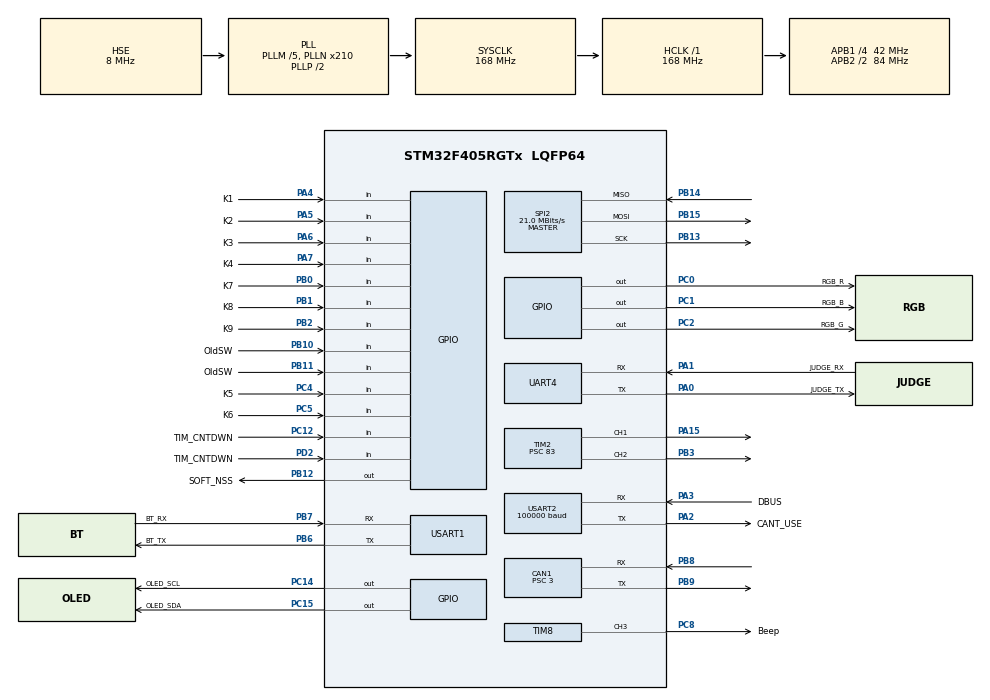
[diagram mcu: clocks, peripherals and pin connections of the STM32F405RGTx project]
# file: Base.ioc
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CAN1.ABOM=ENABLE
CAN1.BS1=CAN_BS1_9TQ
CAN1.BS2=CAN_BS2_4TQ
CAN1.CalculateTimeBit=1000
CAN1.CalculateTimeQuantum=71.42857142857143
CAN1.Prescaler=3
Dma.Request0=UART4_RX
Dma.Request1=USART1_RX
Dma.Request2=USART2_RX
Dma.UART4_RX.0.Channel=DMA_CHANNEL_4
Dma.UART4_RX.0.Direction=DMA_PERIPH_TO_MEMORY
Dma.UART4_RX.0.FIFOMode=DMA_FIFOMODE_DISABLE
Dma.UART4_RX.0.FIFOThreshold=DMA_FIFO_THRESHOLD_FULL
Dma.UART4_RX.0.Instance=DMA1_Stream2
Dma.UART4_RX.0.MemBurst=DMA_MBURST_SINGLE
Dma.UART4_RX.0.MemDataAlignment=DMA_MDATAALIGN_BYTE
Dma.UART4_RX.0.MemInc=DMA_MINC_ENABLE
Dma.UART4_RX.0.Mode=DMA_NORMAL
Dma.UART4_RX.0.PeriphBurst=DMA_PBURST_SINGLE
Dma.UART4_RX.0.PeriphDataAlignment=DMA_PDATAALIGN_BYTE
Dma.UART4_RX.0.PeriphInc=DMA_PINC_DISABLE
Dma.UART4_RX.0.Priority=DMA_PRIORITY_LOW
Dma.USART1_RX.1.Channel=DMA_CHANNEL_4
Dma.USART1_RX.1.Direction=DMA_PERIPH_TO_MEMORY
Dma.USART1_RX.1.FIFOMode=DMA_FIFOMODE_DISABLE
Dma.USART1_RX.1.FIFOThreshold=DMA_FIFO_THRESHOLD_FULL
Dma.USART1_RX.1.Instance=DMA2_Stream2
Dma.USART1_RX.1.MemBurst=DMA_MBURST_SINGLE
Dma.USART1_RX.1.MemDataAlignment=DMA_MDATAALIGN_BYTE
Dma.USART1_RX.1.MemInc=DMA_MINC_ENABLE
Dma.USART1_RX.1.Mode=DMA_NORMAL
Dma.USART1_RX.1.PeriphBurst=DMA_PBURST_SINGLE
Dma.USART1_RX.1.PeriphDataAlignment=DMA_PDATAALIGN_BYTE
Dma.USART1_RX.1.PeriphInc=DMA_PINC_DISABLE
Dma.USART1_RX.1.Priority=DMA_PRIORITY_LOW
Dma.USART2_RX.2.Channel=DMA_CHANNEL_4
Dma.USART2_RX.2.Direction=DMA_PERIPH_TO_MEMORY
Dma.USART2_RX.2.FIFOMode=DMA_FIFOMODE_DISABLE
Dma.USART2_RX.2.FIFOThreshold=DMA_FIFO_THRESHOLD_FULL
Dma.USART2_RX.2.Instance=DMA1_Stream5
Dma.USART2_RX.2.MemBurst=DMA_MBURST_SINGLE
Dma.USART2_RX.2.MemDataAlignment=DMA_MDATAALIGN_BYTE
Dma.USART2_RX.2.MemInc=DMA_MINC_ENABLE
Dma.USART2_RX.2.Mode=DMA_NORMAL
Dma.USART2_RX.2.PeriphBurst=DMA_PBURST_SINGLE
Dma.USART2_RX.2.PeriphDataAlignment=DMA_PDATAALIGN_BYTE
Dma.USART2_RX.2.PeriphInc=DMA_PINC_DISABLE
Dma.USART2_RX.2.Priority=DMA_PRIORITY_LOW
FREERTOS.INCLUDE_uxTaskGetStackHighWaterMark=0
FREERTOS.INCLUDE_vTaskDelayUntil=1
FREERTOS.Tasks01=defaultTask,-2,128,StartDefaultTask
FREERTOS.configUSE_TIMERS=1
Mcu.Family=STM32F4
Mcu.Name=STM32F405RGTx
Mcu.Package=LQFP64
NVIC.CAN1_RX0_IRQn=true\:6\:0\:true
NVIC.DMA1_Stream2_IRQn=true\:8\:0\:true
NVIC.DMA1_Stream5_IRQn=true\:8\:0\:true
NVIC.DMA2_Stream2_IRQn=true\:8\:0\:true
NVIC.PriorityGroup=NVIC_PRIORITYGROUP_4
NVIC.UART4_IRQn=true\:6\:0\:true
NVIC.USART1_IRQn=true\:7\:0\:true
NVIC.USART2_IRQn=true\:7\:0\:true
PA0-WKUP.GPIO_Label=JUDGE_TX
PA0-WKUP.GPIO_Mode=GPIO_MODE_AF_PP
PA0-WKUP.GPIO_PuPd=GPIO_PULLUP
PA0-WKUP.GPIO_Speed=GPIO_SPEED_HIGH
PA0-WKUP.Mode=Asynchronous
PA0-WKUP.Signal=UART4_TX
PA1.GPIO_Label=JUDGE_RX
PA1.GPIO_Mode=GPIO_MODE_AF_PP
PA1.GPIO_PuPd=GPIO_PULLUP
PA1.GPIO_Speed=GPIO_SPEED_HIGH
PA1.Mode=Asynchronous
PA1.Signal=UART4_RX
PA13.Mode=Serial-Wire
PA13.Signal=SYS_JTMS-SWDIO
PA14.Mode=Serial-Wire
PA14.Signal=SYS_JTCK-SWCLK
PA15.Signal=S_TIM2_CH1_ETR
PA2.GPIO_Label=CANT_USE
PA2.GPIO_Mode=GPIO_MODE_AF_PP
PA2.GPIO_PuPd=GPIO_PULLUP
PA2.GPIO_Speed=GPIO_SPEED_HIGH
PA2.Mode=Asynchronous
PA2.Signal=USART2_TX
PA3.GPIO_Label=DBUS
PA3.GPIO_Mode=GPIO_MODE_AF_PP
PA3.GPIO_PuPd=GPIO_PULLUP
PA3.GPIO_Speed=GPIO_SPEED_HIGH
PA3.Mode=Asynchronous
PA3.Signal=USART2_RX
PA4.GPIO_Label=K1
PA4.GPIO_Mode=GPIO_MODE_INPUT
PA4.GPIO_PuPd=GPIO_PULLUP
PA4.Signal=GPIO_Input
PA5.GPIO_Label=K2
PA5.GPIO_Mode=GPIO_MODE_INPUT
PA5.GPIO_PuPd=GPIO_PULLUP
PA5.Signal=GPIO_Input
PA6.GPIO_Label=K3
PA6.GPIO_Mode=GPIO_MODE_INPUT
PA6.GPIO_PuPd=GPIO_PULLUP
PA6.Signal=GPIO_Input
PA7.GPIO_Label=K4
PA7.GPIO_Mode=GPIO_MODE_INPUT
PA7.GPIO_PuPd=GPIO_PULLUP
PA7.Signal=GPIO_Input
PB0.GPIO_Label=K7
PB0.GPIO_Mode=GPIO_MODE_INPUT
PB0.GPIO_PuPd=GPIO_PULLUP
PB0.Signal=GPIO_Input
PB1.GPIO_Label=K8
PB1.GPIO_Mode=GPIO_MODE_INPUT
PB1.GPIO_PuPd=GPIO_PULLUP
PB1.Signal=GPIO_Input
PB10.GPIO_Label=OldSW
PB10.GPIO_Mode=GPIO_MODE_INPUT
PB10.GPIO_PuPd=GPIO_PULLUP
PB10.Signal=GPIO_Input
PB11.GPIO_Label=OldSW
PB11.GPIO_Mode=GPIO_MODE_INPUT
PB11.GPIO_PuPd=GPIO_PULLUP
PB11.Signal=GPIO_Input
PB12.GPIO_Label=SOFT_NSS
PB12.GPIO_ModeDefaultOutputPP=GPIO_MODE_OUTPUT_PP
PB12.GPIO_PuPd=GPIO_NOPULL
PB12.GPIO_Speed=GPIO_SPEED_LOW
PB12.Signal=GPIO_Output
PB13.Mode=Full_Duplex_Master
PB13.Signal=SPI2_SCK
PB14.Mode=Full_Duplex_Master
PB14.Signal=SPI2_MISO
PB15.Mode=Full_Duplex_Master
PB15.Signal=SPI2_MOSI
PB2.GPIO_Label=K9
PB2.GPIO_Mode=GPIO_MODE_INPUT
PB2.GPIO_PuPd=GPIO_PULLUP
PB2.Signal=GPIO_Input
PB3.Signal=S_TIM2_CH2
PB6.GPIO_Label=BT_TX
PB6.GPIO_Mode=GPIO_MODE_AF_PP
PB6.GPIO_PuPd=GPIO_PULLUP
PB6.GPIO_Speed=GPIO_SPEED_HIGH
PB6.Mode=Asynchronous
PB6.Signal=USART1_TX
PB7.GPIO_Label=BT_RX
PB7.GPIO_Mode=GPIO_MODE_AF_PP
PB7.GPIO_PuPd=GPIO_PULLUP
PB7.GPIO_Speed=GPIO_SPEED_HIGH
PB7.Mode=Asynchronous
PB7.Signal=USART1_RX
PB8.Mode=Master
PB8.Signal=CAN1_RX
PB9.Mode=Master
PB9.Signal=CAN1_TX
PC0.GPIO_Label=RGB_R
PC0.GPIO_ModeDefaultOutputPP=GPIO_MODE_OUTPUT_PP
PC0.GPIO_PuPd=GPIO_NOPULL
PC0.GPIO_Speed=GPIO_SPEED_LOW
PC0.Signal=GPIO_Output
PC1.GPIO_Label=RGB_B
PC1.GPIO_ModeDefaultOutputPP=GPIO_MODE_OUTPUT_PP
PC1.GPIO_PuPd=GPIO_NOPULL
PC1.GPIO_Speed=GPIO_SPEED_LOW
PC1.Signal=GPIO_Output
PC12.GPIO_Label=TIM_CNTDWN
PC12.GPIO_Mode=GPIO_MODE_INPUT
PC12.GPIO_PuPd=GPIO_PULLUP
PC12.Signal=GPIO_Input
PC14-OSC32_IN.GPIO_Label=OLED_SCL
PC14-OSC32_IN.GPIO_ModeDefaultOutputPP=GPIO_MODE_OUTPUT_PP
PC14-OSC32_IN.GPIO_PuPd=GPIO_NOPULL
PC14-OSC32_IN.GPIO_Speed=GPIO_SPEED_LOW
PC14-OSC32_IN.Signal=GPIO_Output
PC15-OSC32_OUT.GPIO_Label=OLED_SDA
PC15-OSC32_OUT.GPIO_ModeDefaultOutputPP=GPIO_MODE_OUTPUT_PP
PC15-OSC32_OUT.GPIO_PuPd=GPIO_NOPULL
PC15-OSC32_OUT.GPIO_Speed=GPIO_SPEED_LOW
PC15-OSC32_OUT.Signal=GPIO_Output
PC2.GPIO_Label=RGB_G
PC2.GPIO_ModeDefaultOutputPP=GPIO_MODE_OUTPUT_PP
PC2.GPIO_PuPd=GPIO_NOPULL
PC2.GPIO_Speed=GPIO_SPEED_LOW
PC2.Signal=GPIO_Output
PC4.GPIO_Label=K5
PC4.GPIO_Mode=GPIO_MODE_INPUT
PC4.GPIO_PuPd=GPIO_NOPULL
PC4.Signal=GPIO_Input
PC5.GPIO_Label=K6
PC5.GPIO_Mode=GPIO_MODE_INPUT
PC5.GPIO_PuPd=GPIO_NOPULL
PC5.Signal=GPIO_Input
PC8.GPIO_Label=Beep
PC8.GPIO_ModeDefaultPP=GPIO_MODE_AF_PP
PC8.GPIO_PuPd=GPIO_NOPULL
PC8.GPIO_Speed=GPIO_SPEED_LOW
PC8.Signal=S_TIM8_CH3
PD2.GPIO_Label=TIM_CNTDWN
PD2.GPIO_Mode=GPIO_MODE_INPUT
PD2.GPIO_PuPd=GPIO_NOPULL
PD2.Signal=GPIO_Input
PH0-OSC_IN.Mode=HSE-External-Oscillator
PH0-OSC_IN.Signal=RCC_OSC_IN
PH1-OSC_OUT.Mode=HSE-External-Oscillator
PH1-OSC_OUT.Signal=RCC_OSC_OUT
ProjectManager.TargetToolchain=MDK-ARM V5
RCC.48MHZClocksFreq_Value=48000000
RCC.AHBFreq_Value=168000000
RCC.APB1CLKDivider=RCC_HCLK_DIV4
RCC.APB1Freq_Value=42000000
RCC.APB1TimFreq_Value=84000000
RCC.APB2CLKDivider=RCC_HCLK_DIV2
RCC.APB2Freq_Value=84000000
RCC.APB2TimFreq_Value=168000000
RCC.CortexFreq_Value=168000000
RCC.HCLKFreq_Value=168000000
RCC.HSE_VALUE=8000000
RCC.HSI_VALUE=16000000
RCC.LSE_VALUE=32768
RCC.PLLM=5
RCC.PLLN=210
RCC.PLLQ=7
RCC.PLLSourceVirtual=RCC_PLLSOURCE_HSE
RCC.SYSCLKFreq_VALUE=168000000
RCC.SYSCLKSource=RCC_SYSCLKSOURCE_PLLCLK
RCC.VCOOutputFreq_Value=336000000
SH.S_TIM2_CH1_ETR.0=TIM2_CH1,PWM Generation1 CH1
SH.S_TIM2_CH2.0=TIM2_CH2,PWM Generation2 CH2
SH.S_TIM8_CH3.0=TIM8_CH3,PWM Generation3 CH3
SPI2.CalculateBaudRate=21.0 MBits/s
SPI2.Mode=SPI_MODE_MASTER
TIM2.Channel-PWM\ Generation2\ CH2=TIM_CHANNEL_2
TIM2.Period=9999
TIM2.Prescaler=83
TIM8.Channel-PWM\ Generation3\ CH3=TIM_CHANNEL_3
TIM8.Period=199
TIM8.Prescaler=335
TIM8.Pulse-PWM\ Generation3\ CH3=100
TIM8.RepetitionCounter=0
USART2.BaudRate=100000
USART2.Mode=UART_MODE_RX
USART2.Parity=UART_PARITY_EVEN
VP_FREERTOS_VS_ENABLE.Mode=Enabled
VP_RNG_VS_RNG.Mode=RNG_Activate
board=Base

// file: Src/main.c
/**
  ******************************************************************************
  * File Name          : main.c
  * Description        : Main program body
  ******************************************************************************
  *
  * COPYRIGHT(c) 2016 STMicroelectronics
  *
  * Redistribution and use in source and binary forms, with or without modification,
  * are permitted provided that the following conditions are met:
  *   1. Redistributions of source code must retain the above copyright notice,
  *      this list of conditions and the following disclaimer.
  *   2. Redistributions in binary form must reproduce the above copyright notice,
  *      this list of conditions and the following disclaimer in the documentation
  *      and/or other materials provided with the distribution.
  *   3. Neither the name of STMicroelectronics nor the names of its contributors
  *      may be used to endorse or promote products derived from this software
  *      without specific prior written permission.
  *
  * THIS SOFTWARE IS PROVIDED BY THE COPYRIGHT HOLDERS AND CONTRIBUTORS "AS IS"
  * AND ANY EXPRESS OR IMPLIED WARRANTIES, INCLUDING, BUT NOT LIMITED TO, THE
  * IMPLIED WARRANTIES OF MERCHANTABILITY AND FITNESS FOR A PARTICULAR PURPOSE ARE
  * DISCLAIMED. IN NO EVENT SHALL THE COPYRIGHT HOLDER OR CONTRIBUTORS BE LIABLE
  * FOR ANY DIRECT, INDIRECT, INCIDENTAL, SPECIAL, EXEMPLARY, OR CONSEQUENTIAL
  * DAMAGES (INCLUDING, BUT NOT LIMITED TO, PROCUREMENT OF SUBSTITUTE GOODS OR
  * SERVICES; LOSS OF USE, DATA, OR PROFITS; OR BUSINESS INTERRUPTION) HOWEVER
  * CAUSED AND ON ANY THEORY OF LIABILITY, WHETHER IN CONTRACT, STRICT LIABILITY,
  * OR TORT (INCLUDING NEGLIGENCE OR OTHERWISE) ARISING IN ANY WAY OUT OF THE USE
  * OF THIS SOFTWARE, EVEN IF ADVISED OF THE POSSIBILITY OF SUCH DAMAGE.
  *
  ******************************************************************************
  */
#include "stm32f4xx_hal.h"
#include "cmsis_os.h"
#include "can.h"
#include "dma.h"
#include "rng.h"
#include "spi.h"
#include "tim.h"
#include "usart.h"
#include "gpio.h"

/* USER CODE BEGIN PV */

/* Private variables ---------------------------------------------------------*/

/* USER CODE END PV */

void SystemClock_Config(void);
void MX_FREERTOS_Init(void);

/* USER CODE BEGIN PFP */
/* Private function prototypes -----------------------------------------------*/

/* USER CODE END PFP */

int main(void)
{

  /* MCU Configuration----------------------------------------------------------*/

  /* Reset of all peripherals, Initializes the Flash interface and the Systick. */
  HAL_Init();

  /* Configure the system clock */
  SystemClock_Config();

  /* Initialize all configured peripherals */
  MX_GPIO_Init();
  MX_DMA_Init();
  MX_CAN1_Init();
  MX_RNG_Init();
  MX_SPI2_Init();
  MX_TIM2_Init();
  MX_TIM8_Init();
  MX_UART4_Init();
  MX_USART1_UART_Init();
  MX_USART2_UART_Init();

  /* Call init function for freertos objects (in freertos.c) */
  MX_FREERTOS_Init();

  /* Start scheduler */
  osKernelStart();

  /* We should never get here as control is now taken by the scheduler */

  /* Infinite loop */
  while (1)
  {

  }

}

/** System Clock Configuration
*/
void SystemClock_Config(void)
{

  RCC_OscInitTypeDef RCC_OscInitStruct;
  RCC_ClkInitTypeDef RCC_ClkInitStruct;

  __PWR_CLK_ENABLE();

  __HAL_PWR_VOLTAGESCALING_CONFIG(PWR_REGULATOR_VOLTAGE_SCALE1);

  RCC_OscInitStruct.OscillatorType = RCC_OSCILLATORTYPE_HSE;
  RCC_OscInitStruct.HSEState = RCC_HSE_ON;
  RCC_OscInitStruct.PLL.PLLState = RCC_PLL_ON;
  RCC_OscInitStruct.PLL.PLLSource = RCC_PLLSOURCE_HSE;
  RCC_OscInitStruct.PLL.PLLM = 5;
  RCC_OscInitStruct.PLL.PLLN = 210;
  RCC_OscInitStruct.PLL.PLLP = RCC_PLLP_DIV2;
  RCC_OscInitStruct.PLL.PLLQ = 7;
  HAL_RCC_OscConfig(&RCC_OscInitStruct);

  RCC_ClkInitStruct.ClockType = RCC_CLOCKTYPE_SYSCLK|RCC_CLOCKTYPE_PCLK1
                              |RCC_CLOCKTYPE_PCLK2;
  RCC_ClkInitStruct.SYSCLKSource = RCC_SYSCLKSOURCE_PLLCLK;
  RCC_ClkInitStruct.AHBCLKDivider = RCC_SYSCLK_DIV1;
  RCC_ClkInitStruct.APB1CLKDivider = RCC_HCLK_DIV4;
  RCC_ClkInitStruct.APB2CLKDivider = RCC_HCLK_DIV2;
  HAL_RCC_ClockConfig(&RCC_ClkInitStruct, FLASH_LATENCY_5);

  HAL_SYSTICK_Config(HAL_RCC_GetHCLKFreq()/1000);

  HAL_SYSTICK_CLKSourceConfig(SYSTICK_CLKSOURCE_HCLK);

}

/************************ (C) COPYRIGHT STMicroelectronics *****END OF FILE****/

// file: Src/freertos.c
/**
  ******************************************************************************
  * File Name          : freertos.c
  * Description        : Code for freertos applications
  ******************************************************************************
  *
  * COPYRIGHT(c) 2016 STMicroelectronics
  *
  * Redistribution and use in source and binary forms, with or without modification,
  * are permitted provided that the following conditions are met:
  *   1. Redistributions of source code must retain the above copyright notice,
  *      this list of conditions and the following disclaimer.
  *   2. Redistributions in binary form must reproduce the above copyright notice,
  *      this list of conditions and the following disclaimer in the documentation
  *      and/or other materials provided with the distribution.
  *   3. Neither the name of STMicroelectronics nor the names of its contributors
  *      may be used to endorse or promote products derived from this software
  *      without specific prior written permission.
  *
  * THIS SOFTWARE IS PROVIDED BY THE COPYRIGHT HOLDERS AND CONTRIBUTORS "AS IS"
  * AND ANY EXPRESS OR IMPLIED WARRANTIES, INCLUDING, BUT NOT LIMITED TO, THE
  * IMPLIED WARRANTIES OF MERCHANTABILITY AND FITNESS FOR A PARTICULAR PURPOSE ARE
  * DISCLAIMED. IN NO EVENT SHALL THE COPYRIGHT HOLDER OR CONTRIBUTORS BE LIABLE
  * FOR ANY DIRECT, INDIRECT, INCIDENTAL, SPECIAL, EXEMPLARY, OR CONSEQUENTIAL
  * DAMAGES (INCLUDING, BUT NOT LIMITED TO, PROCUREMENT OF SUBSTITUTE GOODS OR
  * SERVICES; LOSS OF USE, DATA, OR PROFITS; OR BUSINESS INTERRUPTION) HOWEVER
  * CAUSED AND ON ANY THEORY OF LIABILITY, WHETHER IN CONTRACT, STRICT LIABILITY,
  * OR TORT (INCLUDING NEGLIGENCE OR OTHERWISE) ARISING IN ANY WAY OUT OF THE USE
  * OF THIS SOFTWARE, EVEN IF ADVISED OF THE POSSIBILITY OF SUCH DAMAGE.
  *
  ******************************************************************************
  */

#include "FreeRTOS.h"
#include "task.h"
#include "cmsis_os.h"

/* USER CODE BEGIN Includes */
#include "task_underpan.h"
#include "task_check.h"
#include "timer_canSender.h"
#include "task_debug.h"
#include "task_init.h"
/* USER CODE END Includes */

osThreadId defaultTaskHandle;

void StartDefaultTask(void const * argument);

void MX_FREERTOS_Init(void); /* (MISRA C 2004 rule 8.1) */

/* Hook prototypes */

/* Init FreeRTOS */

void MX_FREERTOS_Init(void) {

  /* Create the thread(s) */
  /* definition and creation of defaultTask */
  osThreadDef(defaultTask, StartDefaultTask, osPriorityLow, 0, 128);
  defaultTaskHandle = osThreadCreate(osThread(defaultTask), NULL);

  /* USER CODE BEGIN RTOS_THREADS */
  /* add threads, ... */
  initTaskThreadCreate(osPriorityHigh);
  /* USER CODE END RTOS_THREADS */

}

/* StartDefaultTask function */
void StartDefaultTask(void const * argument)
{

  for(;;)
  {
    osDelay(1);
  }
}

/************************ (C) COPYRIGHT STMicroelectronics *****END OF FILE****/
